AUTOSAR XML (schema 4-3-0)
package /CAN_MCU_R1/ISignalGroup
  i signal group CAN_MCU_R1_SG_EOP_FVT_R_Local1: i-signal=[CAN_MCU_R1_EOP_FVT_R_ActualSpd_Sta, CAN_MCU_R1_EOP_FVT_R_CSInvalid_Sta, CAN_MCU_R1_EOP_FVT_R_CanLoss_Sta, CAN_MCU_R1_EOP_FVT_R_EnableOff_Sta, CAN_MCU_R1_EOP_FVT_R_HallSigErr_Sta, CAN_MCU_R1_EOP_FVT_R_Local1_CS_Sta, CAN_MCU_R1_EOP_FVT_R_Local1_RC_Sta, CAN_MCU_R1_EOP_FVT_R_OverTempBCK_Sta, CAN_MCU_R1_EOP_FVT_R_OverTemp_Sta, CAN_MCU_R1_EOP_FVT_R_OverVol_Sta, CAN_MCU_R1_EOP_FVT_R_PumpReady_Sta, CAN_MCU_R1_EOP_FVT_R_RCInvalid_Sta, CAN_MCU_R1_EOP_FVT_R_RunStatus_Sta, CAN_MCU_R1_EOP_FVT_R_StartFailure_Sta, CAN_MCU_R1_EOP_FVT_R_UnderVol_Sta], system-signal-group=CAN_MCU_R1_SG_EOP_FVT_R_Local1
  i signal group CAN_MCU_R1_SG_MCU_FVT_R_Local1: i-signal=[CAN_MCU_R1_MCU_FVT_R_Local1_CS_Sta, CAN_MCU_R1_MCU_FVT_R_Local1_RC_Sta, CAN_MCU_R1_MCU_FVT_R_OPCStartOn_Req, CAN_MCU_R1_MCU_FVT_R_OilPmpTarSpd_Req], system-signal-group=CAN_MCU_R1_SG_MCU_FVT_R_Local1
package /CAN_MCU_R1/Cluster
  can cluster CAN_MCU_R1: baudrate=500
    can physical channel CAN_MCU_R1: comm-connectors=ConnCAN_MCU_R1
      frame CAN_MCU_R1_DiagPhysReqToEOP_FVT_R: id 0x6C3, frame-length=8, can-addressing-mode=STANDARD, can-fd-frame-support=false, can-frame-rx-behavior=CAN-20, can-frame-tx-behavior=CAN-20
        n pdu CAN_MCU_R1_DiagPhysReqToEOP_FVT_R: length=8
      frame CAN_MCU_R1_DiagRespFromEOP_FVT_R: id 0x643, frame-length=8, can-addressing-mode=STANDARD, can-fd-frame-support=false, can-frame-rx-behavior=CAN-20, can-frame-tx-behavior=CAN-20
        n pdu CAN_MCU_R1_DiagRespFromEOP_FVT_R: length=8
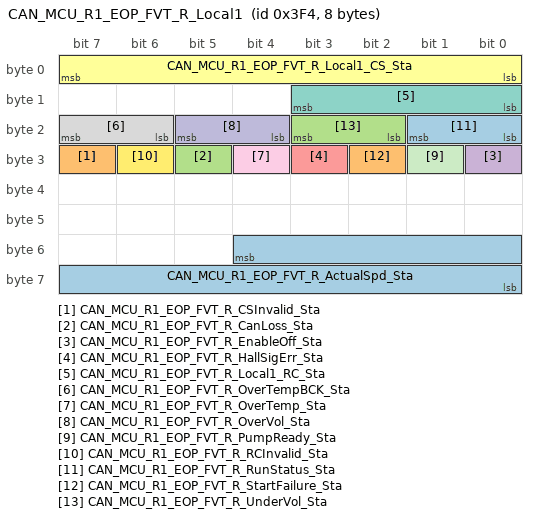
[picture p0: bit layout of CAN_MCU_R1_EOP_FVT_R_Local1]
      frame CAN_MCU_R1_EOP_FVT_R_Local1: id 0x3F4, frame-length=8, can-addressing-mode=STANDARD, can-fd-frame-support=false, can-frame-rx-behavior=CAN-20, can-frame-tx-behavior=CAN-20
        pdu CAN_MCU_R1_EOP_FVT_R_Local1: length=8, minimum-delay=0.0, transmission-mode-true-timing=cyclic-timing=time-period=0.01, unused-bit-pattern=0
          mapping CAN_MCU_R1_SG_EOP_FVT_R_Local1: i-signal-group=CAN_MCU_R1_SG_EOP_FVT_R_Local1, start-position=0, transfer-property=PENDING
          signal CAN_MCU_R1_EOP_FVT_R_ActualSpd_Sta: start 52, 13 bit, big-endian, i-signal-type=PRIMITIVE, init-value=constant-reference=Init_CAN_MCU_R1_EOP_FVT_R_ActualSpd_Sta, base-type=uint16, implementation-data-type=uint16, transfer-property=PENDING
          signal CAN_MCU_R1_EOP_FVT_R_CSInvalid_Sta: start 31, 1 bit, big-endian, i-signal-type=PRIMITIVE, init-value=constant-reference=Init_CAN_MCU_R1_EOP_FVT_R_CSInvalid_Sta, base-type=uint8, implementation-data-type=uint8, transfer-property=PENDING
          signal CAN_MCU_R1_EOP_FVT_R_CanLoss_Sta: start 29, 1 bit, big-endian, i-signal-type=PRIMITIVE, init-value=constant-reference=Init_CAN_MCU_R1_EOP_FVT_R_CanLoss_Sta, base-type=uint8, implementation-data-type=uint8, transfer-property=PENDING
          signal CAN_MCU_R1_EOP_FVT_R_EnableOff_Sta: start 24, 1 bit, big-endian, i-signal-type=PRIMITIVE, init-value=constant-reference=Init_CAN_MCU_R1_EOP_FVT_R_EnableOff_Sta, base-type=uint8, implementation-data-type=uint8, transfer-property=PENDING
          signal CAN_MCU_R1_EOP_FVT_R_HallSigErr_Sta: start 27, 1 bit, big-endian, i-signal-type=PRIMITIVE, init-value=constant-reference=Init_CAN_MCU_R1_EOP_FVT_R_HallSigErr_Sta, base-type=uint8, implementation-data-type=uint8, transfer-property=PENDING
          signal CAN_MCU_R1_EOP_FVT_R_Local1_CS_Sta: start 7, 8 bit, big-endian, i-signal-type=PRIMITIVE, init-value=constant-reference=Init_CAN_MCU_R1_EOP_FVT_R_Local1_CS_Sta, base-type=uint8, implementation-data-type=uint8, transfer-property=PENDING
          signal CAN_MCU_R1_EOP_FVT_R_Local1_RC_Sta: start 11, 4 bit, big-endian, i-signal-type=PRIMITIVE, init-value=constant-reference=Init_CAN_MCU_R1_EOP_FVT_R_Local1_RC_Sta, base-type=uint8, implementation-data-type=uint8, transfer-property=PENDING
          signal CAN_MCU_R1_EOP_FVT_R_OverTempBCK_Sta: start 23, 2 bit, big-endian, i-signal-type=PRIMITIVE, init-value=constant-reference=Init_CAN_MCU_R1_EOP_FVT_R_OverTempBCK_Sta, base-type=uint8, implementation-data-type=uint8, transfer-property=PENDING
          signal CAN_MCU_R1_EOP_FVT_R_OverTemp_Sta: start 28, 1 bit, big-endian, i-signal-type=PRIMITIVE, init-value=constant-reference=Init_CAN_MCU_R1_EOP_FVT_R_OverTemp_Sta, base-type=uint8, implementation-data-type=uint8, transfer-property=PENDING
          signal CAN_MCU_R1_EOP_FVT_R_OverVol_Sta: start 21, 2 bit, big-endian, i-signal-type=PRIMITIVE, init-value=constant-reference=Init_CAN_MCU_R1_EOP_FVT_R_OverVol_Sta, base-type=uint8, implementation-data-type=uint8, transfer-property=PENDING
          signal CAN_MCU_R1_EOP_FVT_R_PumpReady_Sta: start 25, 1 bit, big-endian, i-signal-type=PRIMITIVE, init-value=constant-reference=Init_CAN_MCU_R1_EOP_FVT_R_PumpReady_Sta, base-type=uint8, implementation-data-type=uint8, transfer-property=PENDING
          signal CAN_MCU_R1_EOP_FVT_R_RCInvalid_Sta: start 30, 1 bit, big-endian, i-signal-type=PRIMITIVE, init-value=constant-reference=Init_CAN_MCU_R1_EOP_FVT_R_RCInvalid_Sta, base-type=uint8, implementation-data-type=uint8, transfer-property=PENDING
          signal CAN_MCU_R1_EOP_FVT_R_RunStatus_Sta: start 17, 2 bit, big-endian, i-signal-type=PRIMITIVE, init-value=constant-reference=Init_CAN_MCU_R1_EOP_FVT_R_RunStatus_Sta, base-type=uint8, implementation-data-type=uint8, transfer-property=PENDING
          signal CAN_MCU_R1_EOP_FVT_R_StartFailure_Sta: start 26, 1 bit, big-endian, i-signal-type=PRIMITIVE, init-value=constant-reference=Init_CAN_MCU_R1_EOP_FVT_R_StartFailure_Sta, base-type=uint8, implementation-data-type=uint8, transfer-property=PENDING
          signal CAN_MCU_R1_EOP_FVT_R_UnderVol_Sta: start 19, 2 bit, big-endian, i-signal-type=PRIMITIVE, init-value=constant-reference=Init_CAN_MCU_R1_EOP_FVT_R_UnderVol_Sta, base-type=uint8, implementation-data-type=uint8, transfer-property=PENDING
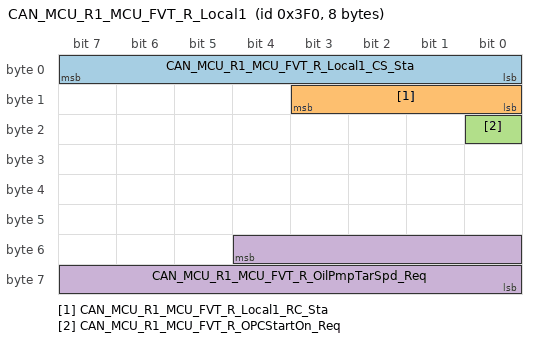
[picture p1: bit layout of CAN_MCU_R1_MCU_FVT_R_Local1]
      frame CAN_MCU_R1_MCU_FVT_R_Local1: id 0x3F0, frame-length=8, can-addressing-mode=STANDARD, can-fd-frame-support=false, can-frame-rx-behavior=CAN-20, can-frame-tx-behavior=CAN-20
        pdu CAN_MCU_R1_MCU_FVT_R_Local1: length=8, minimum-delay=0.0, transmission-mode-true-timing=cyclic-timing=time-period=0.01, unused-bit-pattern=0
          mapping CAN_MCU_R1_SG_MCU_FVT_R_Local1: i-signal-group=CAN_MCU_R1_SG_MCU_FVT_R_Local1, start-position=0, transfer-property=PENDING
          signal CAN_MCU_R1_MCU_FVT_R_Local1_CS_Sta: start 7, 8 bit, big-endian, i-signal-type=PRIMITIVE, init-value=constant-reference=Init_CAN_MCU_R1_MCU_FVT_R_Local1_CS_Sta, base-type=uint8, implementation-data-type=uint8, transfer-property=PENDING
          signal CAN_MCU_R1_MCU_FVT_R_Local1_RC_Sta: start 11, 4 bit, big-endian, i-signal-type=PRIMITIVE, init-value=constant-reference=Init_CAN_MCU_R1_MCU_FVT_R_Local1_RC_Sta, base-type=uint8, implementation-data-type=uint8, transfer-property=PENDING
          signal CAN_MCU_R1_MCU_FVT_R_OPCStartOn_Req: start 16, 1 bit, big-endian, i-signal-type=PRIMITIVE, init-value=constant-reference=Init_CAN_MCU_R1_MCU_FVT_R_OPCStartOn_Req, base-type=uint8, implementation-data-type=uint8, transfer-property=PENDING
          signal CAN_MCU_R1_MCU_FVT_R_OilPmpTarSpd_Req: start 52, 13 bit, big-endian, i-signal-type=PRIMITIVE, init-value=constant-reference=Init_CAN_MCU_R1_MCU_FVT_R_OilPmpTarSpd_Req, base-type=uint16, implementation-data-type=uint16, transfer-property=PENDING
package /CAN_MCU_R1/ConstantSpecification
  21 x constant specification:
    Init_CAN_MCU_R1_EOP_FVT_R_ActualSpd_Sta: value-spec=0
    Init_CAN_MCU_R1_EOP_FVT_R_CSInvalid_Sta: value-spec=0
    Init_CAN_MCU_R1_EOP_FVT_R_CanLoss_Sta: value-spec=0
    Init_CAN_MCU_R1_EOP_FVT_R_EnableOff_Sta: value-spec=0
    Init_CAN_MCU_R1_EOP_FVT_R_HallSigErr_Sta: value-spec=0
    Init_CAN_MCU_R1_EOP_FVT_R_Local1_CS_Sta: value-spec=0
    Init_CAN_MCU_R1_EOP_FVT_R_Local1_RC_Sta: value-spec=0
    Init_CAN_MCU_R1_EOP_FVT_R_OverTempBCK_Sta: value-spec=0
    Init_CAN_MCU_R1_EOP_FVT_R_OverTemp_Sta: value-spec=0
    Init_CAN_MCU_R1_EOP_FVT_R_OverVol_Sta: value-spec=0
    Init_CAN_MCU_R1_EOP_FVT_R_PumpReady_Sta: value-spec=0
    Init_CAN_MCU_R1_EOP_FVT_R_RCInvalid_Sta: value-spec=0
    Init_CAN_MCU_R1_EOP_FVT_R_RunStatus_Sta: value-spec=0
    Init_CAN_MCU_R1_EOP_FVT_R_StartFailure_Sta: value-spec=0
    Init_CAN_MCU_R1_EOP_FVT_R_UnderVol_Sta: value-spec=0
    Init_CAN_MCU_R1_MCU_FVT_R_Local1_CS_Sta: value-spec=0
    Init_CAN_MCU_R1_MCU_FVT_R_Local1_RC_Sta: value-spec=0
    Init_CAN_MCU_R1_MCU_FVT_R_OPCStartOn_Req: value-spec=0
    Init_CAN_MCU_R1_MCU_FVT_R_OilPmpTarSpd_Req: value-spec=0
    Init_CAN_MCU_R1_SG_EOP_FVT_R_Local1: value-spec=fields=[Init_CAN_MCU_R1_EOP_FVT_R_ActualSpd_Sta, Init_CAN_MCU_R1_EOP_FVT_R_CSInvalid_Sta, Init_CAN_MCU_R1_EOP_FVT_R_CanLoss_Sta, Init_CAN_MCU_R1_EOP_FVT_R_EnableOff_Sta, Init_CAN_MCU_R1_EOP_FVT_R_HallSigErr_Sta, Init_CAN_MCU_R1_EOP_FVT_R_Local1_CS_Sta, Init_CAN_MCU_R1_EOP_FVT_R_Local1_RC_Sta, Init_CAN_MCU_R1_EOP_FVT_R_OverTempBCK_Sta, Init_CAN_MCU_R1_EOP_FVT_R_OverTemp_Sta, Init_CAN_MCU_R1_EOP_FVT_R_OverVol_Sta, Init_CAN_MCU_R1_EOP_FVT_R_PumpReady_Sta, Init_CAN_MCU_R1_EOP_FVT_R_RCInvalid_Sta, Init_CAN_MCU_R1_EOP_FVT_R_RunStatus_Sta, Init_CAN_MCU_R1_EOP_FVT_R_StartFailure_Sta, Init_CAN_MCU_R1_EOP_FVT_R_UnderVol_Sta]
    Init_CAN_MCU_R1_SG_MCU_FVT_R_Local1: value-spec=fields=[Init_CAN_MCU_R1_MCU_FVT_R_Local1_CS_Sta, Init_CAN_MCU_R1_MCU_FVT_R_Local1_RC_Sta, Init_CAN_MCU_R1_MCU_FVT_R_OPCStartOn_Req, Init_CAN_MCU_R1_MCU_FVT_R_OilPmpTarSpd_Req]
package /CAN_MCU_R1/ImplementationDataTypes
  impl type DT_CAN_MCU_R1_SG_EOP_FVT_R_Local1: category=STRUCTURE
    15 x element, all with category=TYPE_REFERENCE:
      CAN_MCU_R1_EOP_FVT_R_ActualSpd_Sta: implementation-data-type=uint16
      CAN_MCU_R1_EOP_FVT_R_CSInvalid_Sta: implementation-data-type=uint8
      CAN_MCU_R1_EOP_FVT_R_CanLoss_Sta: implementation-data-type=uint8
      CAN_MCU_R1_EOP_FVT_R_EnableOff_Sta: implementation-data-type=uint8
      CAN_MCU_R1_EOP_FVT_R_HallSigErr_Sta: implementation-data-type=uint8
      CAN_MCU_R1_EOP_FVT_R_Local1_CS_Sta: implementation-data-type=uint8
      CAN_MCU_R1_EOP_FVT_R_Local1_RC_Sta: implementation-data-type=uint8
      CAN_MCU_R1_EOP_FVT_R_OverTempBCK_Sta: implementation-data-type=uint8
      CAN_MCU_R1_EOP_FVT_R_OverTemp_Sta: implementation-data-type=uint8
      CAN_MCU_R1_EOP_FVT_R_OverVol_Sta: implementation-data-type=uint8
      CAN_MCU_R1_EOP_FVT_R_PumpReady_Sta: implementation-data-type=uint8
      CAN_MCU_R1_EOP_FVT_R_RCInvalid_Sta: implementation-data-type=uint8
      CAN_MCU_R1_EOP_FVT_R_RunStatus_Sta: implementation-data-type=uint8
      CAN_MCU_R1_EOP_FVT_R_StartFailure_Sta: implementation-data-type=uint8
      CAN_MCU_R1_EOP_FVT_R_UnderVol_Sta: implementation-data-type=uint8
  impl type DT_CAN_MCU_R1_SG_MCU_FVT_R_Local1: category=STRUCTURE
    4 x element, all with category=TYPE_REFERENCE:
      CAN_MCU_R1_MCU_FVT_R_Local1_CS_Sta: implementation-data-type=uint8
      CAN_MCU_R1_MCU_FVT_R_Local1_RC_Sta: implementation-data-type=uint8
      CAN_MCU_R1_MCU_FVT_R_OPCStartOn_Req: implementation-data-type=uint8
      CAN_MCU_R1_MCU_FVT_R_OilPmpTarSpd_Req: implementation-data-type=uint16
